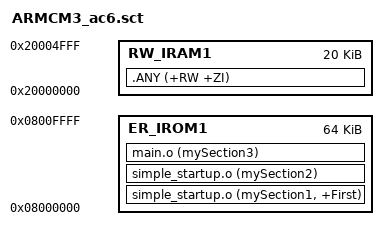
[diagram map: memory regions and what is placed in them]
LR_IROM1 0x08000000 0x00010000  {    ; load region size_region
  ER_IROM1 0x08000000 0x00010000  {  ; load address = execution address
   simple_startup.o (mySection1, +First)
   simple_startup.o (mySection2)
   main.o (mySection3)
   
   ; .ANY (+RO)
  }
  RW_IRAM1 0x20000000 0x00005000  {  ; RW data
   .ANY (+RW +ZI)
  }
}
